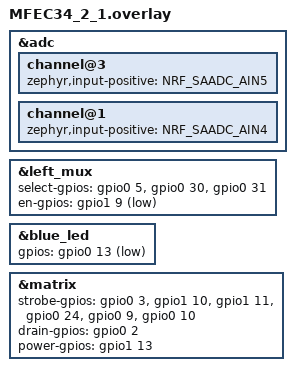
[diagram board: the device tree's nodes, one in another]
/*
 * Copyright (c) 2020 The ZMK Contributors
 *
 * SPDX-License-Identifier: MIT
 */

#include <zephyr/dt-bindings/dt-util.h>
#include <zephyr/dt-bindings/adc/adc.h>
#include <zephyr/dt-bindings/gpio/nordic-nrf-gpio.h>

#include <freq.h>

&adc {
    // Battery Sensing
    channel@3 {
        zephyr,input-positive = <NRF_SAADC_AIN5>; /* P0.29 */
    };

    // EC Read
    channel@1 {
        zephyr,input-positive = <NRF_SAADC_AIN4>; /* P0.28 */
    };
};

&left_mux {
    select-gpios
        = <&gpio0 5 GPIO_ACTIVE_HIGH>
        , <&gpio0 30  GPIO_ACTIVE_HIGH>
        , <&gpio0 31 GPIO_ACTIVE_HIGH>
        ;
    en-gpios = <&gpio1 9 GPIO_ACTIVE_LOW>;
};


&blue_led {
    gpios = <&gpio0 13 GPIO_ACTIVE_LOW>;
};

&matrix {
    strobe-gpios
        = <&gpio0 3 (GPIO_ACTIVE_HIGH| NRF_GPIO_DRIVE_H0H1)>
        , <&gpio1 10 (GPIO_ACTIVE_HIGH| NRF_GPIO_DRIVE_H0H1)>
        , <&gpio1 11 (GPIO_ACTIVE_HIGH| NRF_GPIO_DRIVE_H0H1)>
        , <&gpio0 24 (GPIO_ACTIVE_HIGH| NRF_GPIO_DRIVE_H0H1)>
        , <&gpio0 9 (GPIO_ACTIVE_HIGH| NRF_GPIO_DRIVE_H0H1)>
        , <&gpio0 10 (GPIO_ACTIVE_HIGH| NRF_GPIO_DRIVE_H0H1)>
        ;

    drain-gpios = <&gpio0 2 (GPIO_ACTIVE_HIGH | NRF_GPIO_DRIVE_H0H1)>;
    power-gpios = <&gpio1 13 (GPIO_ACTIVE_HIGH | NRF_GPIO_DRIVE_H0H1)>;
};

